# max32520 register map
Vendor: Maxim-Integrated; Series: ARMCM4; File version: 1.0
CPU: CM4 r2p1, little endian, MPU, FPU, 3 interrupt priority bits
Registers are 32-bit, read-write, reset 0x0 unless marked. A register's access mark holds for its fields unless they carry their own. Offsets are from the block's base; [hi:lo] are bit positions.

## SFE — Serial Flash Emulator.
Base 0x400A0000
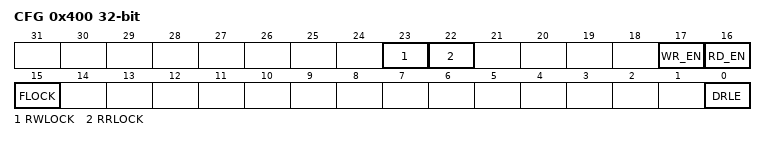
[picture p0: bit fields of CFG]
0x400 CFG — SFE Configuration Register.
  [23] RWLOCK — RAM Write Lock.
  [22] RRLOCK — RAM Read Lock.
  [17] WR_EN — RAM Write Enable.
  [16] RD_EN — RAM Read Enable.
  [15] FLOCK — Flash Lock.
  [0] DRLE — Data Rise Launch Edge Enable.
0x408 HFSA — SFE Host Flash Start Address Register.
  [31:10] HFSA — Serial Flash Host Flash Start Address.
0x40C HRSA — SFE Host RAM Start Address Register.
  [31:10] HRSA — Serial Flash Host RAM Start Address.
0x410 SFDP_SBA — SFE Discoverable Parameter System Base Register.
  [31:8] SFDP_SBA — SFDP upper 24 bits System Base Address.
0x414 FLASH_SBA — Flash System Base Address Register.
  [31:10] FLASH_SBA — FLASH upper 22 bits System Base Address.
0x418 FLASH_STA — Flash System Top Address Register.
  [31:10] FLASH_STA — FLASH upper 22 bits System Top Address.
0x41C RAM_SBA — RAM System Base Address Register.
  [31:10] RAM_SBA — RAM upper 22 bits System Base Address.
0x420 RAM_STA — RAM System Top Address Register.
  [31:10] RAM_STA — RAM upper 22 bits System Top Address.

## SIR — System Initialization Registers.
Base 0x40000400
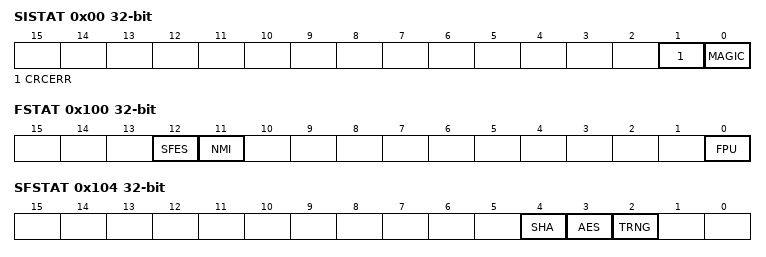
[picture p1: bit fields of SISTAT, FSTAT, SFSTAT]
0x00 SISTAT ro — System Initialization Status Register.
  [1] CRCERR — CRC Error Status. This bit is set by the system initialization block following power-up.
    on read: 0=noError (No CRC errors occurred during the read of the OTP memory block.); 1=error (A CRC error occurred while reading the OTP. The address of the failure location in the OTP memory is stored in the ERRADDR register.)
  [0] MAGIC — Magic Word Validation. This bit is set by the system initialization block following power-up.
    on read: 0=magicNotSet (Magic word was not set (OTP has not been initialized properly).); 1=magicSet (Magic word was set (OTP contains valid settings).)
0x04 ERRADDR ro — Read-only field set by the SIB block if a CRC error occurs during the read of the OTP memory. Contains the failing address in OTP memory (when CRCERR equals 1).
0x100 FSTAT ro — funcstat register.
  [all] fields
    0=no; 1=yes
  [12] SFES — SFES function.
  [11] NMI — NMI function.
  [0] FPU — FPU Function.
0x104 SFSTAT ro — secfuncstat register.
  [all] fields
    0=no; 1=yes
  [4] SHA — SHA function.
  [3] AES — AES function.
  [2] TRNG — TRNG function.

## TMR0 — 32-bit reloadable timer that can be used for timing and event counting.
Base 0x40010000
Same registers: TMR1 0x40011000, TMR2 0x40012000, TMR3 0x40013000
0x00 CNT reset 0x1 — Count. This register stores the current timer count.
0x04 CMP reset 0xFFFF — Compare. This register stores the compare value, which is used to set the maximum count value to initiate a reload of the timer to 0x0001.
0x08 PWM — PWM. This register stores the value that is compared to the current timer count.
0x0C INTR write-1-clears — Clear Interrupt. Writing a value (0 or 1) to a bit in this register clears the associated interrupt.
  [0] IRQ_CLR — Clear Interrupt.
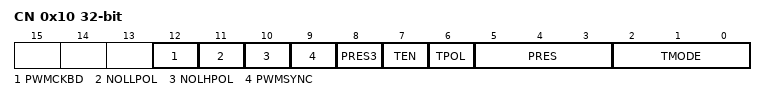
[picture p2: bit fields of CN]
0x10 CN — Timer Control Register.
  [12] PWMCKBD — Timer PWM output 0A Mode Disable.
    1=dis (Disable.); 0=en (Enable.)
  [11] NOLLPOL — Timer PWM output 0A' polarity bit.
    0=dis (Disable.); 1=en (Enable.)
  [10] NOLHPOL — Timer PWM output 0A polarity bit.
    0=dis (Disable.); 1=en (Enable.)
  [9] PWMSYNC — Timer PWM Synchronization Mode Enable.
    0=dis (Disable.); 1=en (Enable.)
  [8] PRES3 — MSB of prescaler value.
  [7] TEN — Timer Enable.
    0=dis (Disable.); 1=en (Enable.)
  [6] TPOL — Timer input/output polarity bit.
    0=Active High; 1=Active Low
  [5:3] PRES — Prescaler. Set the Timer's prescaler value. The prescaler divides the PCLK input to the timer and sets the Timer's Count Clock, F_CNT_CLK = PCLK (HZ) /prescaler. The Timer's prescaler setting is a 4-bit value with pres3:pres[2:0].
    0=div1 (Divide by 1.); 1=div2 (Divide by 2.); 2=div4 (Divide by 4.); 3=div8 (Divide by 8.); 4=div16 (Divide by 16.); 5=div32 (Divide by 32.); 6=div64 (Divide by 64.); 7=div128 (Divide by 128.)
  [2:0] TMODE — Timer Mode.
    0=One Shot Mode; 1=Continuous Mode; 2=Counter Mode; 3=pwm (PWM Mode.); 4=Capture Mode; 5=Compare Mode; 6=Gated Mode; 7=Capture/Compare Mode
